# netx90_app register map
File version: 1.0
CPU: CM4 r0p1, little endian, MPU, FPU, 4 interrupt priority bits, 78 interrupts
Registers are 32-bit, read-write, reset 0x0 unless marked. A register's access mark holds for its fields unless they carry their own. Offsets are from the block's base; [hi:lo] are bit positions; {n}, {i} and the like mark numbered series.

## endat0_app
Base 0xFF802000
Same registers: endat1_app 0xFF802040
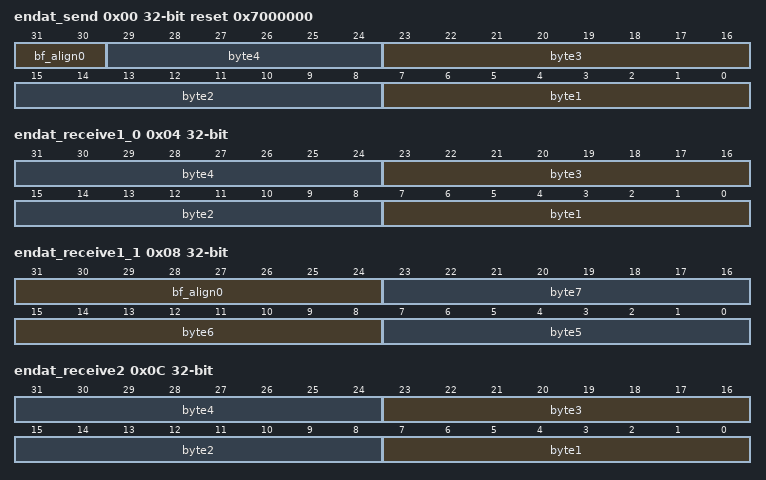
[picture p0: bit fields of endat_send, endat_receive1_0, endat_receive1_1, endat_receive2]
0x00 endat_send reset 0x7000000 (reset mask 0x3FFFFFFF) — Send register The send register contains data to be transmitted to the EnDat encoder. Mode command MRS code/address/port address (depends on the mode command) Parameters/instructions (depends on the mode command)
  [31:30] bf_align0 — bitField alignment value for aeabi compatibility
  [29:24] byte4 — Mode bits M[5:0]
  [23:16] byte3 — MRS code / Address / Port address A[7:0]
  [15:8] byte2 — Parameters / Instructions D[15:0]
  [7:0] byte1 — Parameters / Instructions D[7:0]
0x04 endat_receive1_0 ro — Receive register 1 Depending on the transmitted type 2.1 mode command, receive register 1 contains different data. With EnDat type 2.2 mode commands and with SSI, the position value is always entered into receive-Reg 1.
  [8n-1:8n-8] byte{n} (n=1..4)
0x08 endat_receive1_1 ro (reset mask 0xFFFFFF) — Receive register 1
  [31:24] bf_align0 — bitField alignment value for aeabi compatibility
  [23:16] byte7
  [15:8] byte6
  [7:0] byte5
0x0C endat_receive2 ro — Receive register 2 If a type 2.2 mode command was sent, receive register 2 will contain the contents of additional information 2 and its CRC. This data is to be interpreted in accordance with the EnDat Interface Description. In SSI protocol mode with double-word transmission, the redundant position value is stored here (right-aligned).
  [8n-1:8n-8] byte{n} (n=1..4)
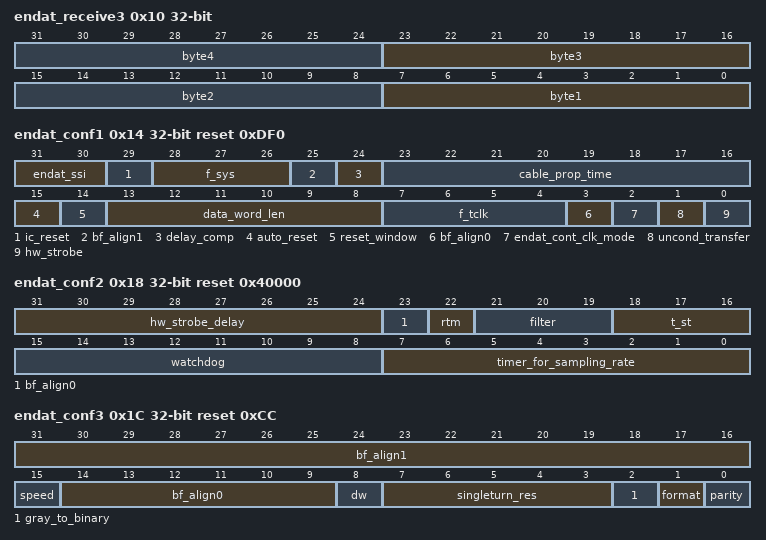
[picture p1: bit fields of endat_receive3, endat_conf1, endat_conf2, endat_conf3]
0x10 endat_receive3 ro — Receive register 3 If a type 2.2 mode command was sent, receive register 3 will contain the contents of additional information 1 and its CRC. This data is to be interpreted in accordance with the EnDat Interface Description.
  [8n-1:8n-8] byte{n} (n=1..4)
0x14 endat_conf1 reset 0xDF0 (reset mask 0xFDFFFFF7) — Configuration register 1
  [31:30] endat_ssi — These two bits set either the EnDat (0x2) or the SSI (0x1) transmission mode. Values 0x0 and 0x3 are not permitted. Note: For debugging purposes, this function may also be used to perform an internal status engine software reset without clearing of the other internal registers.
  [29] ic_reset — Setting of this bit has the effect that the entire interface component is reset to its initial state. IC reset inactive = 0 IC reset active = 1
  [28:26] f_sys — The system frequency actually used must be selected here. 64/48/32/50/100 MHz = 000/010/100/101/110
  [25] bf_align1 — bitField alignment value for aeabi compatibility
  [24] delay_comp — Delay compensation. This bit switches propagation delay compensation on. When this bit is set, propagation time measurement is performed with the next data transmission to the EnDat encoder. The interface component determines the cable propagation time and saves this in conf_reg1. This value is used to determine propagation delay compensation. To measure the propagation time again, the delay compensation bit must be reset and set again. For 16-bit access it must be considered that the measured cable propagation time value is overwritten with 00/h. Delay compensation off = 0 Delay compensation on = 1 In SSI mode, this bit is always on: Delay compensation off = 0 (SSI mode)
  [23:16] cable_prop_time — The cable propagation time determined by the interface component is stored here. (The application may change this value. If that is the case the status registers propagation time measurement (LZM) bit will automatically be reset). The binary value has a step width of one system clock. At a system clock of 64 MHz, this corresponds to a setting range from 0 us to 3.98 us in steps of 15.6 ns. The basic setting is 00 hex
  [15] auto_reset — Autom. reset (automatic reset). If this bit is set, resetting of the status register and error register is performed automatically Autom. reset = 0 Resetting of the above-mentioned registers must be performed by the application. Autom. reset = 1 Resetting of the above-mentioned registers is done automatically. However, this resetting only occurs in the next EnDat transmission with the start of data reception. For safety applications: autom. reset = 0
  [14] reset_window — The set bit allows resetting of the status and error register only within a defined time period. Reset window = 0 Resetting of the registers mentioned above can be performed anytime (i.e. without considering malfunctions). Reset Window = 1 Resetting of the registers mentioned above must be performed within a defined time period for acceptance by the protocol engine. For safety applications: reset window = 1
  [13:8] data_word_len — Here the data word length is set binary with 6 bits for EnDat or SSI. The permissible setting range for EnDat is from 8 bits to 48 bits. The permissible setting range for SSI is from 8 bits to 48 bits. Data word length = 0 bits = 00 1000 : Data word length = 13 bits = 00 1101 : Data word length = 48 bits = 11 0000 Note: The Data word length has to set to 40/d bit while using mode command 'encoder transmit test values'. Note: In SSI mode the additionally required clock cycle for the parity bit is generated automatically by the circuit.
  [7:4] f_tclk — Setting (4 bit) of transmission rate for EnDat and SSI from 100 kHz to 1 MHz (SSI) or 16 MHz (EnDat). Transmission frequency = 100kHz = 1111 Transmission frequency = 200kHz = 1110 Transmission frequency = 1MHz = 1101 Transmission frequency = 2MHz = 1100 Transmission frequency = 4.16MHz = 1011 Transmission frequency = 8.33MHz = 0110 Transmission frequency = 16.67MHz = 0000..0011
  [3] bf_align0 — bitField alignment value for aeabi compatibility
  [2] endat_cont_clk_mode — This bit is used to select the EnDat continuous clock mode. Continuous clock off = 0 Continuous clock on = 1
  [1] uncond_transfer — This bit defines the unconditional data transfer to receive registers 1, 2, 3, 4 on completion of a data transmission process, despite a flag being set in the status register. Data transfer according to flag set in the status register = 0 Data transfer despite the flag in the status register = 1 For safety applications uncond_transfer = 1 must be set.
  [0] hw_strobe — 1: Enables external /STR signal as strobe signal
0x18 endat_conf2 reset 0x40000 (reset mask 0xFF7FFFFF) — Configuration register 2
  [31:24] hw_strobe_delay — Here the application can enter a value for the HW strobe delay. The binary value has a step width of one system clock. Setting 00 = Off, 3..255=3..255 system clock cycles The values 1, 2 are not permissible. At a system clock of 64 MHz, this corresponds to a value range from 46.88 ns to 3.98 us in steps of 15.6 ns.
  [23] bf_align0 — bitField alignment value for aeabi compatibility
  [22] rtm — Activates the recovery time measurement that is then performed after each EnDat transmission with the mode command 1-1 'Encoder transmit position value and selection of memory area' with MRS code 0x43 (selection of 2nd word of position value 2). RTM=0 Recovery time measurement is deactivated (default setting after reset) RTM=1 Recovery time measurement is activated
  [21:19] filter — The digital filter for the Data_RC data input can be adjusted in eight steps (3 bits) as shown in the table below. The filter setting value corresponds to system clock cycles. Setting 000 = Off Setting 001 = 3 Setting 010 = 4 Setting 011 = 5 Setting 100 = 6 Setting 101 = 10 Setting 110 = 20 Setting 111 = 40 Setting 000 001 010 011 100 101 110 111 Note on the application: The filter must be set according to the transmission rate of the serial interface to the encoder. Example: fTCLK = 1 MHz (corresponds to 64 system clock cycles with CLK = 64 MHz) For the filter, 1/10 of the fTCLK must be set. That means 6 system clock cycles leads to setting: 100
  [18:16] t_st — This time is to be set in accordance with EnDat specification. The set time has an accuracy of 0.1 us. Setting 000 = 0.5 * TCLK Setting 001 = 0.5 us Setting 010 = 1 us Setting 011 = 1.5 us Setting 100 = 2 us Setting 101 = 4 us Setting 110 = 8 us Setting 111 = 10 us
  [15:8] watchdog — 256 different watchdog time values can be set. In the default setting 00 hex or 80 hex the watchdog is off.
  [7:0] timer_for_sampling_rate — 256 different sampling rates can be set. In the default setting 00 hex or 80 hex the timer is off.
0x1C endat_conf3 reset 0xCC (reset mask 0x81FF) — Configuration register 3
  [31:16] bf_align1 — bitField alignment value for aeabi compatibility
  [15] speed — (optional) This bit allows selection of the register width for velocity. 64-bit = 0 32-Bit = 1
  [14:9] bf_align0 — bitField alignment value for aeabi compatibility
  [8] dw — This bit allows a double-word query to be selected with SSI transmission. Double-word query off = 0 Double word query on = 1
  [7:3] singleturn_res — Here the number of steps per revolution is set to binary with 5 bits. This setting is only required for the fir tree format. Singleturn resolution = 13 bits = 0 1101
  [2] gray_to_binary — In SSI transmission mode, Gray code values can be converted here to binary code values. Gray-to-binary conversion inactive = 0 Gray-to-binary conversion inactive = 1
  [1] format — Here the transmission format for SSI transmission is selected. Fir tree: 0 Serial, right-aligned = 1
  [0] parity — Here the parity check for SSI transmission is selected. Parity off = 0 Parity on = 1
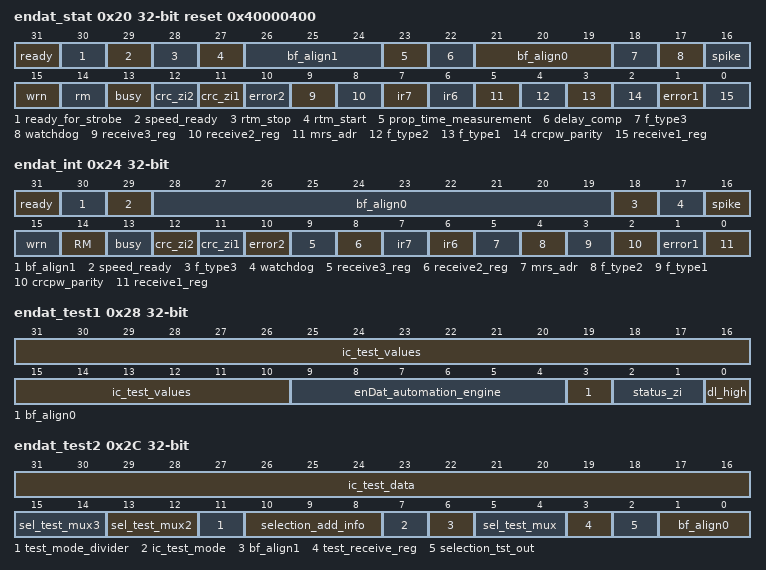
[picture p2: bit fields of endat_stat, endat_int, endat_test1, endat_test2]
0x20 endat_stat reset 0x40000400 (reset mask 0xF8C7FFFF) — Status register The status bits are created by the sequencing controller of the interface component, as required. Status information remains set until it is reset by the application. The application can selectively reset status information with a write command. This occurs by writing 1 to the selected bits. In the event of concurrent access, the internal sequencing controller has priority. This ensures that status information is not 'lost'. The status bits (15:11) are only valid when additional information 1 or 2 has been received. Note on the application: The status register should be read after each data transmission. It provides information about validity of the data contained in the receive registers. The status bits must be reset in order that the internal sequencing controller can recognize a renewed setting of the status bits. Note: Each bit (except for LZM, LZK, Ready for Strobe) can trigger an interrupt (output: INT1). Masking is performed with the interrupt mask register. If a bit that has been set (and thus has triggered an interrupt) is reset, the INT1 output changes from low to three-state if no other bit has triggered an interrupt.
  [31] ready — If the ready bit is set, the status register is completely updated. All checks have been performed. Data transmission is not yet completed, however, meaning that the EnDat protocol automation machine is not yet ready again. No Ready = 0 Ready = 1
  [30] ready_for_strobe — This bit reports that data transmission has ended and that the EnDat protocol automation machine is ready for the next transmission. The time values Recovery time 1 (tm) and Recovery time 2 (tR) as specified in the EnDat specification are completed. No Ready = 0 Ready = 1 This bit cannot be reset by writing a 1 to the respective bit as this is a status display of the current conditions of internal automation engines. The bit cannot cause an interrupt.
  [29] speed_ready — (optional). This bit reports that a new velocity value has been calculated. No new velocity value calculated = 0 New velocity value calculated = 1
  [28] rtm_stop — This bit indicates the end of the recovery time, if conf2(22)=1 during EnDat transmission with mode command 1-1 'Encoder transmit position value and selection of memory area' with MRS code 0x43 (selection of 2nd word of position value 2)
  [27] rtm_start — This bit indicates the beginning of the recovery time, if conf2(22)=1 during EnDat transmission with mode command 1-1 'Encoder transmit position value and selection of memory area' with MRS code 0x43 (selection of 2nd word of position value 2)
  [26:24] bf_align1 — bitField alignment value for aeabi compatibility
  [23] prop_time_measurement — (LZM). This bit reports that propagation time measurement was successfully completed. Condition: propagation delay compensation LZK in conf_reg1 is set. If the value for propagation delay compensation in configuration register 1 is corrected by the application, this bit will automatically be reset. LZM incomplete = 0 LZM complete = 1
  [22] delay_comp — (LZK). This bit reports if propagation delay compensation is active. If propagation delay compensation in configuration register 1 is switched off, this bit and propagation time measurement will automatically be reset. LZK inactive = 0 LZK active = 1 Neither the LZM nor the LZK bit can be reset by writing a 1 to the respective bit as this is a status display of the current conditions of internal automation engines. Neither of the two bits can cause an interrupt.
  [21:19] bf_align0 — bitField alignment value for aeabi compatibility
  [18] f_type3 — Type II error (transmission layer) triggers F type III. Error recognition occurs in the EnDat master. The error did not occur = 0 The error occurred = 1
  [17] watchdog — Reports triggering of the watchdog. Condition: watchdog in conf_reg2 is set. Watchdog not triggered = 0 Watchdog triggered = 1
  [16] spike — Reports that a Spike was detected at the data input port. Condition: filter in conf_reg1 is set. No spike = 0 Spike occurred = 1
  [15] wrn — Contains the WRN status bit as transmitted in the EnDat protocol. WRN = 0 WRN = 1
  [14] rm — Contains the RM status bit as transmitted in the EnDat protocol. RM = 0 RM = 1
  [13] busy — Contains the Busy status bit as transmitted in the EnDat protocol. Busy = 0 Busy = 1
  [12] crc_zi2 — During EnDat transmissions, this bit indicates the result of the CRC checking of additional information (ZI2). CRC check of ZI2 okay = 0 CRC check of ZI2 faulty = 1
  [11] crc_zi1 — During EnDat transmissions, this bit indicates the result of the CRC checking of additional information (ZI1). CRC check of ZI2 okay = 0 CRC check of ZI2 faulty = 1
  [10] error2 — Contains the /Error 2 status bit from the EnDat protocol (only with EnDat2.2 commands). /Error2 occurred = 0 /Error2 did not occur = 1
  [9] receive3_reg — This status flag indicates that the data in Receive-Reg3 has been updated. It must be cleared after Receive-Reg3 has been read to allow the interface component to rewrite data. Receive-Reg3 not updated = 0 Receive-Reg3 updated = 1
  [8] receive2_reg — This status flag indicates that the data in Receive-Reg 2 (3) has been updated. It must be cleared after Receive-Reg2 (3) has been read to allow the interface component to rewrite data. Receive-Reg2 (3) not updated = 0 Receive-Reg2 (3) updated = 1
  [7] ir7 — This bit indicates the state of input pin /IR7. Input /IR7 is at high level = 0 Input /IR7 is at low level = 1
  [6] ir6 — This bit indicates an H/L edge at input pin /IR6. No H/L edge transition at input /IR6 = 0 H/L edge transition has occurred at input /IR6R6 = 1
  [5] mrs_adr — The occurrence of an addressing or acknowledgement error is shown here as described in the EnDat Interface specification. The errors (F type I / II) are special cases of MRS/address errors, i.e. they are a sub-quantity of these. Accordingly, whenever a type I or type II error is identified, the MRS/Adr bit is set. For example, if an MRS/address bit is recognized incorrectly due to a disturbance, only the MRS/Adr status bit will be set, not the F TYP I/II bits. No acknowledgement or addressing error has occurred = 0 An acknowledgement or addressing error has occurred = 1
  [4] f_type2 — Shows type II error handling in accordance with the EnDat specification at Annex A2. A type II error did not occur = 0 A type II error occurred = 1
  [3] f_type1 — Shows type I error handling in accordance with the EnDat specification at Annex A2. A type I error did not occur = 0 A type I error occurred = 1
  [2] crcpw_parity — This bit has two meanings. With EnDat transmission it represents the result of the CRC check of the received value (position value, parameter or test value). With SSI transmission it shows the result of the parity check. Condition: parity check in conf-Reg1 is switched on. CRC check or parity check okay = 0 CRC and parity check faulty = 1
  [1] error1 — The status bit error1 from the EnDat protocol is entered here. Error1 did not occur = 0 Error1 occurred = 1
  [0] receive1_reg — This status flag indicates that the data in Receive-Reg 1 has been updated. It must be cleared after Receive-Reg1 has been read to allow the interface component to rewrite data there. Receive-Reg1 not updated = 0 Receive-Reg1 updated = 1 Note: This flag is ignored if the uncond_transfer bit is enabled in conf-Reg 1.
0x24 endat_int (reset mask 0xA007FFFF) — Interrupt mask The interrupt mask register is for the masking of the status registers interrupt sources. All bits shown in the status register (except for LZM, LZK, Ready for Strobe) can generate an interrupt. The bit assignments of the interrupt mask register are identical to those of the status register. An interrupt is allowed by setting the corresponding bit to 1. The INT output changes from three-state to low.
  [31] ready
  [30] bf_align1 — bitField alignment value for aeabi compatibility
  [29] speed_ready
  [28:19] bf_align0 — bitField alignment value for aeabi compatibility
  [18] f_type3
  [17] watchdog
  [16] spike
  [15] wrn
  [14] RM
  [13] busy
  [12] crc_zi2
  [11] crc_zi1
  [10] error2
  [9] receive3_reg
  [8] receive2_reg
  [7] ir7
  [6] ir6
  [5] mrs_adr
  [4] f_type2
  [3] f_type1
  [2] crcpw_parity
  [1] error1
  [0] receive1_reg
0x28 endat_test1 ro (reset mask 0xFFFFFFF7) — Test register 1
  [31:10] ic_test_values
  [9:4] enDat_automation_engine
  [3] bf_align0 — bitField alignment value for aeabi compatibility
  [2:1] status_zi — Allows testing of the IC-internal automation machine. IC sends no clocks for additional information = 00 IC sends clocks for one unit of additional information 1 = 01 IC sends clocks for one unit of additional information 2 = 10 IC sends clocks for two units of additional information (1+2) = 11
  [0] dl_high — For control of the EnDat automation machine.
0x2C endat_test2 (reset mask 0xFFFFFFBC) — Test register 2
  [31:16] ic_test_data — RTM value - Counter value of the recovery time measurement if conf2(22)=1. Updated after the completion of the recovery time tm measurement during the EnDat transmission with mode command 1-1 'Encoder transmit position value and selection of memory area' with MRS code 0x43 (selection of 2nd word of position value 2). With conf2(22)=0, data for the recovery time measurement tm are not valid. Writing to the test register sets the internal counter of the recovery time measurement to the value of the 'write data' (31:16) - Init word or start value of the recovery time measurement. The value of the internal measuring counter is incremented with the system frequency during the time tm, and the carry is discarded.
  [15:14] sel_test_mux3 — (For testing at IC manufacturing site, internal resources can be read via test register 3) Write value test register 3 = 00 (Content written to test register 3 via the I/O port.) Test values counter TM measurement = 01 TM_High_Err & TM_low_Err & F_TM & TM_CT2 &TM_CT1 Limit values for TM measurement = 10 C_WT_HIGH & C_WT_LOW & C_HIGH & C_LOW Test values internal OEM Reg = 11 (only available in customer-specific versions)
  [13:12] sel_test_mux2 — (For testing at IC manufacturing site, internal resources can be read via test register 4) Test_Mode_Divider = 0: Selection of test multiplexer 2: Test value Pos1b (Pos1 - Off2) = 00 Test value Pos1c (Pos1 DIV nsrPos1) = 01 Test value Pos1d (Pos1 MOD srM) = 10 Test value Pos2 = 11 Test_Mode_Divider = 1 Selection of test multiplexer 2: Test value quotient (divider) = 00 Test value remainder (divider) = 01
  [11] test_mode_divider — (For testing at IC manufacturing site, internal resources can be read via test register 4) Standard operating mode = 0 Test mode active = 1
  [10:8] selection_add_info — The number of required additional information units (ZI) can also be selected manually(alternatively to implemented ZI automation resources) Automated resources active = 0 00 IC sends clocks for one unit of additional information 1 = 0 01 IC sends clocks for one unit of additional information 2 = 0 10 IC sends clocks for two units of additional information (1+2) = 0 11 IC sends no clocks for additional information = 1 xx
  [7] ic_test_mode — The IC can be switched to a special test mode, allowing the testing of internal modules Standard application mode = 0 Special test mode = 1
  [6] bf_align1 — bitField alignment value for aeabi compatibility
  [5:4] sel_test_mux — (for testing at IC manufacturing site, internal resources can be read) Standard operating mode = 00 Central pre-dividers = 01 Start bit counter = 10 Delay counter and register, additional information bit = 11
  [3] test_receive_reg — Standard operating mode = TST receive_reg = 0 Test mode for receive register = TST receive_reg = 1 By writing to the address of the receive registers, the content of test register 2 (bits (31:16) is transferred them. It is not possible to directly write to a receive register via the parallel port.
  [2] selection_tst_out — For testing, the TST_OUT_PIN pin is assigned as follows: Internal (delayed by synchronization) DATA_RC_INT = 0 This signal is the signal that belongs to data strobe pulse.
  [1:0] bf_align0 — bitField alignment value for aeabi compatibility
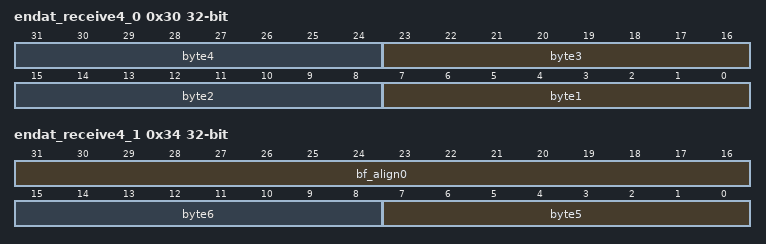
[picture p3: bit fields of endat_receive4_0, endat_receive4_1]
0x30 endat_receive4_0 ro — Receive register 4 Receive register 4 contains position value 2 (Pos2), which is put together from the additional information 1 of Cycles 2, 3 and 4. Test function: with the test register 2 bits (13:12), internal test values can be read
  [8n-1:8n-8] byte{n} (n=1..4)
0x34 endat_receive4_1 ro (reset mask 0xFFFF) — Receive register 4
  [31:16] bf_align0 — bitField alignment value for aeabi compatibility
  [15:8] byte6
  [7:0] byte5
0x38 endat_sw_strobe wo — SW strobe
  [31:0] sw_strobe — Writing this register will in each case cause the first H/L transition of the TCLK transmission clock signal.
0x3C endat_id ro — Identification register The soft-macro specification (ID) is stored here. This information is helpful for automated configuration by higher-level user software. E22: Designates the latest EnDat 2.2 protocol generation 6: MAZeT-internal designation (E6) xxxx: Consecutive version number (this document is valid for all versions as of xx13.)
